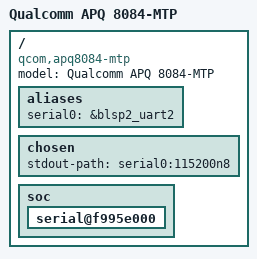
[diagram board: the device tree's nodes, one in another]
#include "qcom-apq8084.dtsi"
#include "qcom-pma8084.dtsi"

/ {
	model = "Qualcomm APQ 8084-MTP";
	compatible = "qcom,apq8084-mtp", "qcom,apq8084";

	aliases {
		serial0 = &blsp2_uart2;
	};

	chosen {
		stdout-path = "serial0:115200n8";
	};

	soc {
		serial@f995e000 {
			status = "okay";
		};
	};
};
